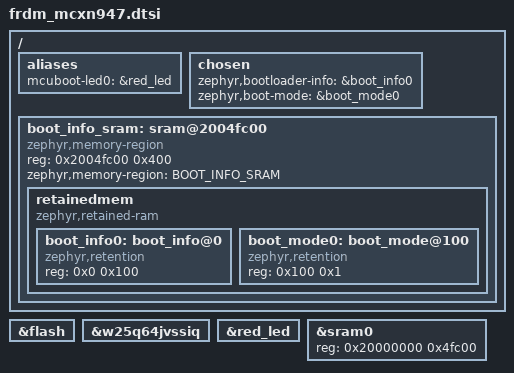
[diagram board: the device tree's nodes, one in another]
/* Delete Zephyr-default partitions before redefining them. */
&flash { /delete-node/ partitions; };
&w25q64jvssiq { /delete-node/ partitions; };

/* Bootloader UI: the entrance button comes from the board's
 * mcuboot-button0 alias (SW2). Point mcuboot-led0 at the red LED for the
 * CONFIG_MCUBOOT_INDICATION_LED build (enabled in conf/frdm_mcxn947.conf);
 * the led_3 node ships status="disabled" upstream, so make it okay here
 * for the status-LED blink (io.c requires a status-okay node with a
 * gpios property). The fork dtsi also applies to the application image,
 * but a status-okay gpio-leds child only claims the pin when the LED
 * driver is compiled in, which CircuitPython does not do. */
&red_led {
	status = "okay";
};

/ {
	aliases {
		mcuboot-led0 = &red_led;
	};
};

#include "frdm_mcxn947-partitions.dtsi"

/* Bootloader info shared-data area: the last KB of this board's RAM, kept
 * out of the managed RAM so neither image clobbers it. The bootloader
 * writes its boot state here on every boot (BOOT_SHARE_DATA_BOOTINFO ->
 * BLINFO TLVs via boot_write_shared_data()); the application reads the
 * same region to answer the SMP bootloader-info command (RETENTION_
 * BOOTLOADER_INFO_TYPE_MCUBOOT). Carved here because this dtsi applies to
 * both images.
 *
 * A second, one-byte retention cell in the same block backs the boot-mode
 * flag (zephyr,boot-mode): the application sets it to request the
 * bootloader's update mode (reset_to_bootloader() / RunMode.UF2) and the
 * bootloader reads and clears it at boot (io_detect_boot_mode()). SRAM
 * content survives the warm reset that follows the request, which is all a
 * button-less entrance needs; a power cycle simply drops the request.
 */
&sram0 {
	reg = <0x20000000 0x4fc00>;
};

/ {
	chosen {
		zephyr,bootloader-info = &boot_info0;
		zephyr,boot-mode = &boot_mode0;
	};

	boot_info_sram: sram@2004fc00 {
		compatible = "zephyr,memory-region", "mmio-sram";
		reg = <0x2004fc00 0x400>;
		zephyr,memory-region = "BOOT_INFO_SRAM";
		status = "okay";

		retainedmem {
			compatible = "zephyr,retained-ram";
			status = "okay";
			#address-cells = <1>;
			#size-cells = <1>;

			boot_info0: boot_info@0 {
				compatible = "zephyr,retention";
				status = "okay";
				reg = <0x0 0x100>;
			};

			boot_mode0: boot_mode@100 {
				compatible = "zephyr,retention";
				status = "okay";
				reg = <0x100 0x1>;
			};
		};
	};
};
